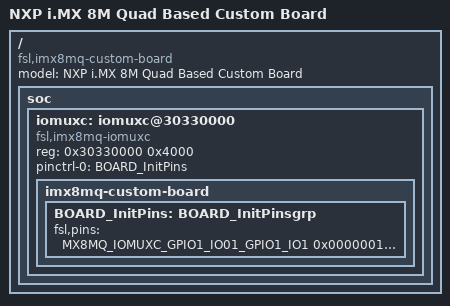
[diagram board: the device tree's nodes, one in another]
/***********************************************************************************************************************
 * This file was generated by the MCUXpresso Config Tools. Any manual edits made to this file
 * will be overwritten if the respective MCUXpresso Config Tools is used to update this file.
 **********************************************************************************************************************/

/*
 * TEXT BELOW IS USED AS SETTING FOR TOOLS *************************************
!!GlobalInfo
product: Pins v7.0
processor: MIMX8MQ6xxxJZ
package_id: MIMX8MQ6DVAJZ
mcu_data: ksdk2_0
processor_version: 7.0.1
pin_labels:
- {pin_num: H6, pin_signal: SAI2_RXD0, label: R1, identifier: R1}
- {pin_num: J5, pin_signal: SAI2_TXC, label: R2, identifier: R2}
- {pin_num: H5, pin_signal: SAI2_MCLK, label: R3, identifier: R3}
- {pin_num: H4, pin_signal: SAI2_TXFS, label: R4, identifier: R4}
- {pin_num: H3, pin_signal: SAI2_RXC, label: R5, identifier: R5}
- {pin_num: J4, pin_signal: SAI2_RXFS, label: R6, identifier: R6}
- {pin_num: K4, pin_signal: SAI5_MCLK, label: R7, identifier: R7}
- {pin_num: K5, pin_signal: SAI5_RXD3, label: R8, identifier: R8}
- {pin_num: T7, pin_signal: GPIO1_IO01, label: R9, identifier: R9}
- {pin_num: J6, pin_signal: GPIO1_IO15, label: R10, identifier: R10}
- {pin_num: N5, pin_signal: GPIO1_IO06, label: R11, identifier: R11}
- {pin_num: P4, pin_signal: GPIO1_IO03, label: R12, identifier: R12}
- {pin_num: M7, pin_signal: GPIO1_IO10, label: R13, identifier: R13}
- {pin_num: L7, pin_signal: GPIO1_IO12, label: R14, identifier: R14}
- {pin_num: K7, pin_signal: GPIO1_IO14, label: R15, identifier: R15}
- {pin_num: K6, pin_signal: GPIO1_IO13, label: R16, identifier: R16}
- {pin_num: N4, pin_signal: SAI5_RXFS, label: FrtPnlUp, identifier: FrtPnlUp}
- {pin_num: M4, pin_signal: SAI5_RXD2, label: FrtPnlDn, identifier: FrtPnlDn}
- {pin_num: M5, pin_signal: SAI5_RXD0, label: FrtPnlOk, identifier: FrtPnlOk}
- {pin_num: J1, pin_signal: SAI1_RXD4, label: CodecSideEnDrv, identifier: CodecSideEnDrv}
- {pin_num: L6, pin_signal: GPIO1_IO11, label: CodecSideIn, identifier: CodecSideIn}
 * BE CAREFUL MODIFYING THIS COMMENT - IT IS YAML SETTINGS FOR TOOLS ***********
 */


/dts-v1/;

#include "skeleton.dtsi"
#include "pins-imx8mq.h"

/ {
    model = "NXP i.MX 8M Quad Based Custom Board";
    compatible = "fsl,imx8mq-custom-board", "fsl,imx8mq-evk", "fsl,imx8mq";

    soc {
        #address-cells = <1>;
        #size-cells = <1>;

        iomuxc: iomuxc@30330000 {
            compatible = "fsl,imx8mq-iomuxc";
            reg = <0x30330000 0x4000>;
        };
    };
};

&iomuxc {
    pinctrl-names = "default_iomuxc";
    pinctrl-0 = <&BOARD_InitPins>;


    imx8mq-custom-board {
        BOARD_InitPins: BOARD_InitPinsgrp {                /*!< Function assigned for the core: Cortex-A53[a53_0] */
/*
 * TEXT BELOW IS USED AS SETTING FOR TOOLS *************************************
BOARD_InitPins:
- options: {callFromInitBoot: 'false', coreID: a53_0}
- pin_list:
  - {pin_num: H6, peripheral: GPIO4, signal: 'gpio_io, 23', pin_signal: SAI2_RXD0, direction: INPUT, PUE: Disabled, DSE: OHM_45}
  - {pin_num: J5, peripheral: GPIO4, signal: 'gpio_io, 25', pin_signal: SAI2_TXC, direction: INPUT, PUE: Disabled}
  - {pin_num: H5, peripheral: GPIO4, signal: 'gpio_io, 27', pin_signal: SAI2_MCLK}
  - {pin_num: H4, peripheral: GPIO4, signal: 'gpio_io, 24', pin_signal: SAI2_TXFS, LVTTL: Disabled, PUE: Disabled, VSEL: VSEL_0}
  - {pin_num: H3, peripheral: GPIO4, signal: 'gpio_io, 22', pin_signal: SAI2_RXC}
  - {pin_num: J4, peripheral: GPIO4, signal: 'gpio_io, 21', pin_signal: SAI2_RXFS}
  - {pin_num: K4, peripheral: GPIO3, signal: 'gpio_io, 25', pin_signal: SAI5_MCLK}
  - {pin_num: K5, peripheral: GPIO3, signal: 'gpio_io, 24', pin_signal: SAI5_RXD3}
  - {pin_num: T7, peripheral: GPIO1, signal: 'gpio_io, 01', pin_signal: GPIO1_IO01}
  - {pin_num: J6, peripheral: GPIO1, signal: 'gpio_io, 15', pin_signal: GPIO1_IO15}
  - {pin_num: N5, peripheral: GPIO1, signal: 'gpio_io, 06', pin_signal: GPIO1_IO06}
  - {pin_num: P4, peripheral: GPIO1, signal: 'gpio_io, 03', pin_signal: GPIO1_IO03}
  - {pin_num: M7, peripheral: GPIO1, signal: 'gpio_io, 10', pin_signal: GPIO1_IO10}
  - {pin_num: L7, peripheral: GPIO1, signal: 'gpio_io, 12', pin_signal: GPIO1_IO12}
  - {pin_num: K7, peripheral: GPIO1, signal: 'gpio_io, 14', pin_signal: GPIO1_IO14}
  - {pin_num: K6, peripheral: GPIO1, signal: 'gpio_io, 13', pin_signal: GPIO1_IO13}
  - {pin_num: N4, peripheral: GPIO3, signal: 'gpio_io, 19', pin_signal: SAI5_RXFS}
  - {pin_num: M4, peripheral: GPIO3, signal: 'gpio_io, 23', pin_signal: SAI5_RXD2}
  - {pin_num: M5, peripheral: GPIO3, signal: 'gpio_io, 21', pin_signal: SAI5_RXD0}
  - {pin_num: J1, peripheral: GPIO4, signal: 'gpio_io, 06', pin_signal: SAI1_RXD4}
  - {pin_num: L6, peripheral: GPIO1, signal: 'gpio_io, 11', pin_signal: GPIO1_IO11}
 * BE CAREFUL MODIFYING THIS COMMENT - IT IS YAML SETTINGS FOR TOOLS ***********
 */
            fsl,pins = <
                MX8MQ_IOMUXC_GPIO1_IO01_GPIO1_IO1          0x00000016
                MX8MQ_IOMUXC_GPIO1_IO03_GPIO1_IO3          0x00000016
                MX8MQ_IOMUXC_GPIO1_IO06_GPIO1_IO6          0x00000016
                MX8MQ_IOMUXC_GPIO1_IO10_GPIO1_IO10         0x00000016
                MX8MQ_IOMUXC_GPIO1_IO11_GPIO1_IO11         0x00000016
                MX8MQ_IOMUXC_GPIO1_IO12_GPIO1_IO12         0x00000016
                MX8MQ_IOMUXC_GPIO1_IO13_GPIO1_IO13         0x00000016
                MX8MQ_IOMUXC_GPIO1_IO14_GPIO1_IO14         0x00000016
                MX8MQ_IOMUXC_GPIO1_IO15_GPIO1_IO15         0x00000016
                MX8MQ_IOMUXC_SAI1_RXD4_GPIO4_IO6           0x00000016
                MX8MQ_IOMUXC_SAI2_MCLK_GPIO4_IO27          0x00000016
                MX8MQ_IOMUXC_SAI2_RXC_GPIO4_IO22           0x00000016
                MX8MQ_IOMUXC_SAI2_RXD0_GPIO4_IO23          0x00000016
                MX8MQ_IOMUXC_SAI2_RXFS_GPIO4_IO21          0x00000016
                MX8MQ_IOMUXC_SAI2_TXC_GPIO4_IO25           0x00000016
                MX8MQ_IOMUXC_SAI2_TXFS_GPIO4_IO24          0x00000016
                MX8MQ_IOMUXC_SAI5_MCLK_GPIO3_IO25          0x00000016
                MX8MQ_IOMUXC_SAI5_RXD0_GPIO3_IO21          0x00000016
                MX8MQ_IOMUXC_SAI5_RXD2_GPIO3_IO23          0x00000016
                MX8MQ_IOMUXC_SAI5_RXD3_GPIO3_IO24          0x00000016
                MX8MQ_IOMUXC_SAI5_RXFS_GPIO3_IO19          0x00000016
            >;
        };
    };
};

/***********************************************************************************************************************
 * EOF
 **********************************************************************************************************************/
